VERSION ""

NS_ :

BS_:

BU_: BMS Charger DART

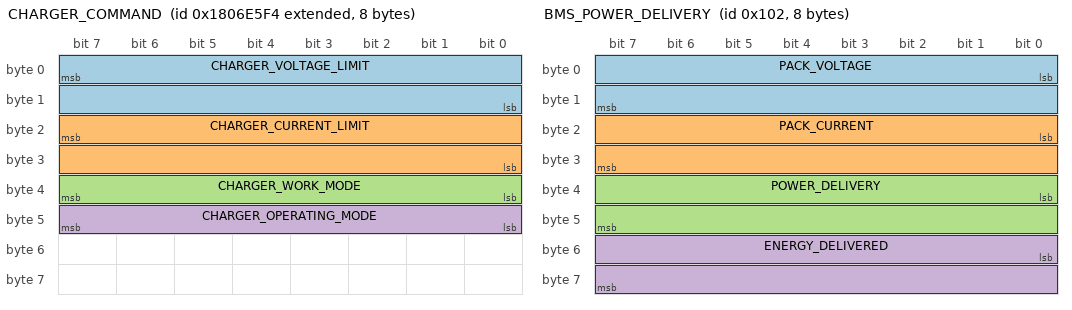
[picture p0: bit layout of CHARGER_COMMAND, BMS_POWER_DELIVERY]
BO_ 2550588916 CHARGER_COMMAND: 8 BMS
 SG_ CHARGER_VOLTAGE_LIMIT : 7|16@0+ (0.1,0) [0|680] "V" Vector__XXX
 SG_ CHARGER_CURRENT_LIMIT : 23|16@0+ (0.1,0) [0|14] "A" Vector__XXX
 SG_ CHARGER_WORK_MODE : 39|8@0+ (1,0) [0|2] "Enum" Vector__XXX
 SG_ CHARGER_OPERATING_MODE : 47|8@0+ (1,0) [0|0] "Enum" Vector__XXX

BO_ 2566869221 CHARGER_RESPONSE: 8 Charger
 SG_ CHARGER_VOLTAGE_OUTPUT : 7|16@0+ (0.1,0) [0|680] "V" Vector__XXX
 SG_ CHARGER_CURRENT_OUTPUT : 23|16@0+ (0.1,0) [0|14] "A" Vector__XXX
 SG_ CHARGER_HARDWARE_PROTECTION : 32|1@0+ (1,0) [0|1] "Bool" Vector__XXX
 SG_ CHARGER_TEMPERATURE_PROTECTION : 33|1@0+ (1,0) [0|1] "Bool" Vector__XXX
 SG_ CHARGER_INPUT_VOLTAGE_STATUS : 35|2@0+ (1,0) [0|1] "Bool" Vector__XXX
 SG_ CHARGER_OUTPUT_UNDERVOLTAGE : 36|1@0+ (1,0) [0|1] "Bool" Vector__XXX
 SG_ CHARGER_OUTPUT_OVERVOLTAGE : 37|1@0+ (1,0) [0|1] "Bool" Vector__XXX
 SG_ CHARGER_OUTPUT_OVERCURRENT : 38|1@0+ (1,0) [0|1] "Bool" Vector__XXX
 SG_ CHARGER_OUTPUT_SHORT_CIRCUIT : 39|1@0+ (1,0) [0|1] "Bool" Vector__XXX
 SG_ CHARGER_COMMAND_FAULT : 40|1@0+ (1,0) [0|1] "Bool" Vector__XXX
 SG_ CHARGER_WORK_STATUS : 42|2@0+ (1,0) [0|3] "Enum" Vector__XXX
 SG_ CHARGER_INITIALIZED : 43|1@0+ (1,0) [0|1] "Bool" Vector__XXX
 SG_ CHARGER_FAN_ENABLED : 44|1@0+ (1,0) [0|1] "Bool" Vector__XXX
 SG_ CHARGER_COOLING_PUMP_ENABLED : 45|1@0+ (1,0) [0|1] "Bool" Vector__XXX
 SG_ CHARGER_CC_STATUS : 49|2@0+ (1,0) [0|3] "Enum" Vector__XXX
 SG_ CHARGER_CP_STATUS : 50|1@0+ (1,0) [0|1] "Bool" Vector__XXX
 SG_ CHARGER_SOCKET_OVERTEMPERATURE : 51|1@0+ (1,0) [0|1] "Bool" Vector__XXX
 SG_ CHARGER_ELECTRONIC_LOCK : 54|3@0+ (1,0) [0|4] "Enum" Vector__XXX
 SG_ CHARGER_S2_SWITCH_CONTROL : 55|1@0+ (1,0) [0|1] "Bool" Vector__XXX
 SG_ CHARGER_TEMPERATURE : 63|8@0+ (1,-40) [-40|205] "C" Vector__XXX

BO_ 257 BMS_STATUS: 8 BMS
 SG_ BMS_ISOSPI_FAULT : 0|1@1+ (1,0) [0|1] "Bool" Vector__XXX
 SG_ BMS_SELF_TEST_FAULT : 1|1@1+ (1,0) [0|1] "Bool" Vector__XXX
 SG_ BMS_SENSE_LINE_FAULT : 2|1@1+ (1,0) [0|1] "Bool" Vector__XXX
 SG_ BMS_UNDERVOLTAGE_FAULT : 3|1@1+ (1,0) [0|1] "Bool" Vector__XXX
 SG_ BMS_OVERVOLTAGE_FAULT : 4|1@1+ (1,0) [0|1] "Bool" Vector__XXX
 SG_ BMS_UNDERTEMPERATURE_FAULT : 5|1@1+ (1,0) [0|1] "Bool" Vector__XXX
 SG_ BMS_OVERTEMPERATURE_FAULT : 6|1@1+ (1,0) [0|1] "Bool" Vector__XXX
 SG_ BMS_FAULT : 7|1@1+ (1,0) [0|0] "Bool" Vector__XXX
 SG_ IMD_FAULT : 8|1@1+ (1,0) [0|0] "Bool" Vector__XXX
 SG_ BMS_CHARGING : 9|1@1+ (1,0) [0|1] "Bool" Vector__XXX
 SG_ BMS_BALANCING : 10|1@1+ (1,0) [0|1] "Bool" Vector__XXX
 SG_ SHUTDOWN_VEHICLE_CLOSED : 11|1@1+ (1,0) [0|1] "Bool" Vector__XXX
 SG_ SHUTDOWN_IMD_CLOSED : 12|1@1+ (1,0) [0|1] "Bool" Vector__XXX
 SG_ SHUTDOWN_BMS_CLOSED : 13|1@1+ (1,0) [0|1] "Bool" Vector__XXX
 SG_ SHUTDOWN_MSD_TSMS_CLOSED : 14|1@1+ (1,0) [0|1] "Bool" Vector__XXX
 SG_ SHUTDOWN_LOOP_BLIP : 15|1@1+ (1,0) [0|1] "Bool" Vector__XXX
 SG_ NEGATIVE_IR_ENABLED : 16|1@1+ (1,0) [0|1] "Bool" Vector__XXX
 SG_ POSITIVE_IR_ENABLED : 17|1@1+ (1,0) [0|1] "Bool" Vector__XXX
 SG_ BMS_EEPROM_STATE : 18|2@1+ (1,0) [0|1] "Enum" Vector__XXX
 SG_ BMS_LTC_0_ISOSPI_FAULT : 32|1@1+ (1,0) [0|1] "Bool" Vector__XXX
 SG_ BMS_LTC_1_ISOSPI_FAULT : 33|1@1+ (1,0) [0|1] "Bool" Vector__XXX
 SG_ BMS_LTC_2_ISOSPI_FAULT : 34|1@1+ (1,0) [0|1] "Bool" Vector__XXX
 SG_ BMS_LTC_3_ISOSPI_FAULT : 35|1@1+ (1,0) [0|1] "Bool" Vector__XXX
 SG_ BMS_LTC_4_ISOSPI_FAULT : 36|1@1+ (1,0) [0|1] "Bool" Vector__XXX
 SG_ BMS_LTC_5_ISOSPI_FAULT : 37|1@1+ (1,0) [0|1] "Bool" Vector__XXX
 SG_ BMS_LTC_6_ISOSPI_FAULT : 38|1@1+ (1,0) [0|1] "Bool" Vector__XXX
 SG_ BMS_LTC_7_ISOSPI_FAULT : 39|1@1+ (1,0) [0|1] "Bool" Vector__XXX
 SG_ BMS_LTC_8_ISOSPI_FAULT : 40|1@1+ (1,0) [0|1] "Bool" Vector__XXX
 SG_ BMS_LTC_9_ISOSPI_FAULT : 41|1@1+ (1,0) [0|1] "Bool" Vector__XXX
 SG_ BMS_LTC_0_SELF_TEST_FAULT : 48|1@1+ (1,0) [0|1] "Bool" Vector__XXX
 SG_ BMS_LTC_1_SELF_TEST_FAULT : 49|1@1+ (1,0) [0|1] "Bool" Vector__XXX
 SG_ BMS_LTC_2_SELF_TEST_FAULT : 50|1@1+ (1,0) [0|1] "Bool" Vector__XXX
 SG_ BMS_LTC_3_SELF_TEST_FAULT : 51|1@1+ (1,0) [0|1] "Bool" Vector__XXX
 SG_ BMS_LTC_4_SELF_TEST_FAULT : 52|1@1+ (1,0) [0|1] "Bool" Vector__XXX
 SG_ BMS_LTC_5_SELF_TEST_FAULT : 53|1@1+ (1,0) [0|1] "Bool" Vector__XXX
 SG_ BMS_LTC_6_SELF_TEST_FAULT : 54|1@1+ (1,0) [0|1] "Bool" Vector__XXX
 SG_ BMS_LTC_7_SELF_TEST_FAULT : 55|1@1+ (1,0) [0|1] "Bool" Vector__XXX
 SG_ BMS_LTC_8_SELF_TEST_FAULT : 56|1@1+ (1,0) [0|1] "Bool" Vector__XXX
 SG_ BMS_LTC_9_SELF_TEST_FAULT : 57|1@1+ (1,0) [0|1] "Bool" Vector__XXX

BO_ 258 BMS_POWER_DELIVERY: 8 BMS
 SG_ PACK_VOLTAGE : 0|16@1+ (0.0125,0) [0|819.2] "V" Vector__XXX
 SG_ PACK_CURRENT : 16|16@1- (0.019073486328125,0) [-625|625] "A" Vector__XXX
 SG_ POWER_DELIVERY : 32|16@1- (0.004,0) [-131.072|131.068] "kW" Vector__XXX
 SG_ ENERGY_DELIVERED : 48|16@1- (0.5,0) [-16.384|16.3835] "Wh" Vector__XXX

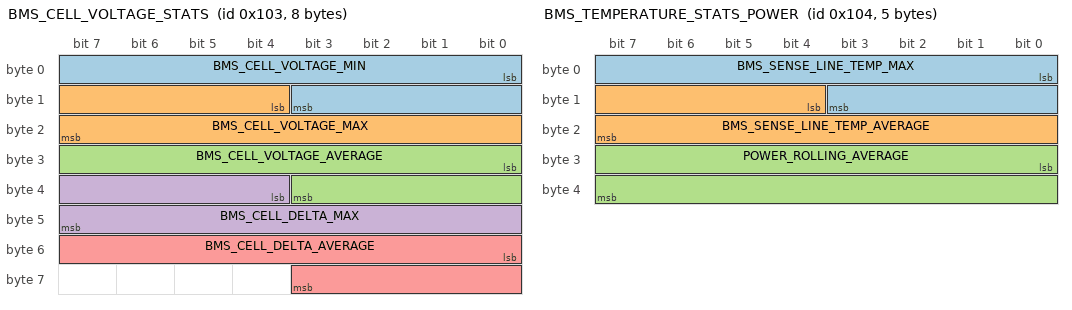
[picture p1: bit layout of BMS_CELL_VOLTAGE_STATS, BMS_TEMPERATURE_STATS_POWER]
BO_ 259 BMS_CELL_VOLTAGE_STATS: 8 Vector__XXX
 SG_ BMS_CELL_VOLTAGE_MIN : 0|12@1+ (0.0016,0) [0|6.552] "V" Vector__XXX
 SG_ BMS_CELL_VOLTAGE_MAX : 12|12@1+ (0.0016,0) [0|6.552] "V" Vector__XXX
 SG_ BMS_CELL_VOLTAGE_AVERAGE : 24|12@1+ (0.0016,0) [0|6.552] "V" Vector__XXX
 SG_ BMS_CELL_DELTA_MAX : 36|12@1+ (0.0016,0) [0|6.552] "V" Vector__XXX
 SG_ BMS_CELL_DELTA_AVERAGE : 48|12@1+ (0.0016,0) [0|6.552] "V" Vector__XXX

BO_ 260 BMS_TEMPERATURE_STATS_POWER: 5 Vector__XXX
 SG_ BMS_SENSE_LINE_TEMP_MAX : 0|12@1+ (0.0625,-106) [-106|150] "C" Vector__XXX
 SG_ BMS_SENSE_LINE_TEMP_AVERAGE : 12|12@1+ (0.0625,-106) [-106|150] "C" Vector__XXX
 SG_ POWER_ROLLING_AVERAGE : 24|16@1- (0.004,0) [-131.072|131.068] "kW" Vector__XXX

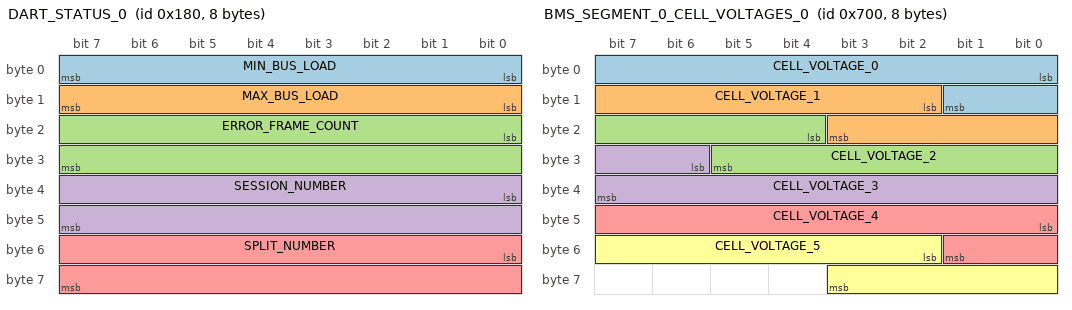
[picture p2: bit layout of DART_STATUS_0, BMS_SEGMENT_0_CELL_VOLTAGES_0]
BO_ 384 DART_STATUS_0: 8 DART
 SG_ MIN_BUS_LOAD : 0|8@1+ (0.6,0) [0|153] "%" Vector__XXX
 SG_ MAX_BUS_LOAD : 8|8@1+ (0.6,0) [0|153] "%" Vector__XXX
 SG_ ERROR_FRAME_COUNT : 16|16@1+ (1,0) [0|65535] "" Vector__XXX
 SG_ SESSION_NUMBER : 32|16@1+ (1,0) [0|65535] "" Vector__XXX
 SG_ SPLIT_NUMBER : 48|16@1+ (1,0) [0|65535] "" Vector__XXX

BO_ 1792 BMS_SEGMENT_0_CELL_VOLTAGES_0: 8 BMS
 SG_ CELL_VOLTAGE_0 : 0|10@1+ (0.0064,0) [0|6.5472] "V" Vector__XXX
 SG_ CELL_VOLTAGE_1 : 10|10@1+ (0.0064,0) [0|6.5472] "V" Vector__XXX
 SG_ CELL_VOLTAGE_2 : 20|10@1+ (0.0064,0) [0|6.5472] "V" Vector__XXX
 SG_ CELL_VOLTAGE_3 : 30|10@1+ (0.0064,0) [0|6.5472] "V" Vector__XXX
 SG_ CELL_VOLTAGE_4 : 40|10@1+ (0.0064,0) [0|6.5472] "V" Vector__XXX
 SG_ CELL_VOLTAGE_5 : 50|10@1+ (0.0064,0) [0|6.5472] "V" Vector__XXX

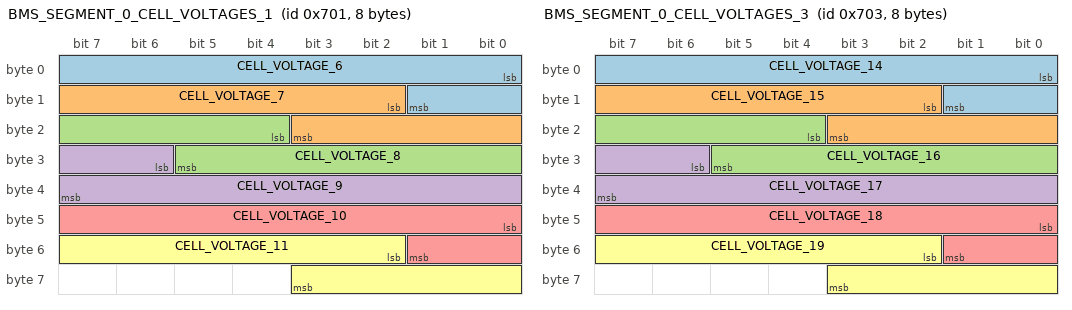
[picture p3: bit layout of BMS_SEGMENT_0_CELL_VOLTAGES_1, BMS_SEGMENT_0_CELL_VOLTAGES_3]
BO_ 1793 BMS_SEGMENT_0_CELL_VOLTAGES_1: 8 BMS
 SG_ CELL_VOLTAGE_6 : 0|10@1+ (0.0064,0) [0|6.5472] "V" Vector__XXX
 SG_ CELL_VOLTAGE_7 : 10|10@1+ (0.0064,0) [0|6.5472] "V" Vector__XXX
 SG_ CELL_VOLTAGE_8 : 20|10@1+ (0.0064,0) [0|6.5472] "V" Vector__XXX
 SG_ CELL_VOLTAGE_9 : 30|10@1+ (0.0064,0) [0|6.5472] "V" Vector__XXX
 SG_ CELL_VOLTAGE_10 : 40|10@1+ (0.0064,0) [0|6.5472] "V" Vector__XXX
 SG_ CELL_VOLTAGE_11 : 50|10@1+ (0.0064,0) [0|6.5472] "V" Vector__XXX

BO_ 1794 BMS_SEGMENT_0_CELL_VOLTAGES_2: 3 BMS
 SG_ CELL_VOLTAGE_12 : 0|10@1+ (0.0064,0) [0|6.5472] "V" Vector__XXX
 SG_ CELL_VOLTAGE_13 : 10|10@1+ (0.0064,0) [0|6.5472] "V" Vector__XXX

BO_ 1795 BMS_SEGMENT_0_CELL_VOLTAGES_3: 8 BMS
 SG_ CELL_VOLTAGE_14 : 0|10@1+ (0.0064,0) [0|6.5472] "V" Vector__XXX
 SG_ CELL_VOLTAGE_15 : 10|10@1+ (0.0064,0) [0|6.5472] "V" Vector__XXX
 SG_ CELL_VOLTAGE_16 : 20|10@1+ (0.0064,0) [0|6.5472] "V" Vector__XXX
 SG_ CELL_VOLTAGE_17 : 30|10@1+ (0.0064,0) [0|6.5472] "V" Vector__XXX
 SG_ CELL_VOLTAGE_18 : 40|10@1+ (0.0064,0) [0|6.5472] "V" Vector__XXX
 SG_ CELL_VOLTAGE_19 : 50|10@1+ (0.0064,0) [0|6.5472] "V" Vector__XXX

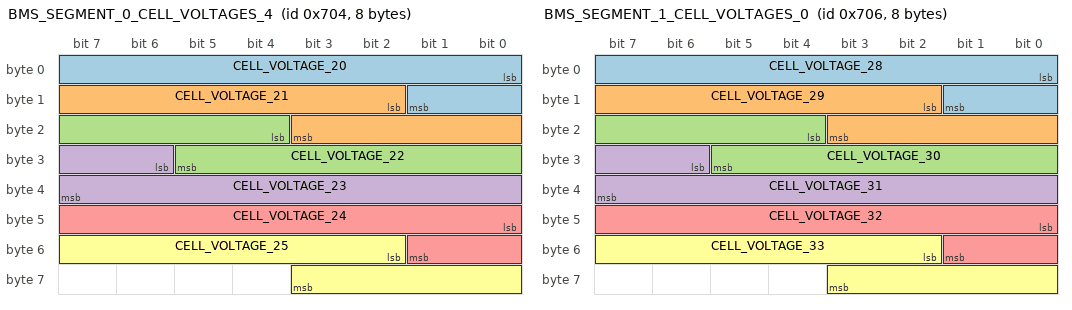
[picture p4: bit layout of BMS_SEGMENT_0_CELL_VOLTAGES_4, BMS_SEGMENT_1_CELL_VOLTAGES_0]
BO_ 1796 BMS_SEGMENT_0_CELL_VOLTAGES_4: 8 BMS
 SG_ CELL_VOLTAGE_20 : 0|10@1+ (0.0064,0) [0|6.5472] "V" Vector__XXX
 SG_ CELL_VOLTAGE_21 : 10|10@1+ (0.0064,0) [0|6.5472] "V" Vector__XXX
 SG_ CELL_VOLTAGE_22 : 20|10@1+ (0.0064,0) [0|6.5472] "V" Vector__XXX
 SG_ CELL_VOLTAGE_23 : 30|10@1+ (0.0064,0) [0|6.5472] "V" Vector__XXX
 SG_ CELL_VOLTAGE_24 : 40|10@1+ (0.0064,0) [0|6.5472] "V" Vector__XXX
 SG_ CELL_VOLTAGE_25 : 50|10@1+ (0.0064,0) [0|6.5472] "V" Vector__XXX

BO_ 1797 BMS_SEGMENT_0_CELL_VOLTAGES_5: 3 BMS
 SG_ CELL_VOLTAGE_26 : 0|10@1+ (0.0064,0) [0|6.5472] "V" Vector__XXX
 SG_ CELL_VOLTAGE_27 : 10|10@1+ (0.0064,0) [0|6.5472] "V" Vector__XXX

BO_ 1798 BMS_SEGMENT_1_CELL_VOLTAGES_0: 8 BMS
 SG_ CELL_VOLTAGE_28 : 0|10@1+ (0.0064,0) [0|6.5472] "V" Vector__XXX
 SG_ CELL_VOLTAGE_29 : 10|10@1+ (0.0064,0) [0|6.5472] "V" Vector__XXX
 SG_ CELL_VOLTAGE_30 : 20|10@1+ (0.0064,0) [0|6.5472] "V" Vector__XXX
 SG_ CELL_VOLTAGE_31 : 30|10@1+ (0.0064,0) [0|6.5472] "V" Vector__XXX
 SG_ CELL_VOLTAGE_32 : 40|10@1+ (0.0064,0) [0|6.5472] "V" Vector__XXX
 SG_ CELL_VOLTAGE_33 : 50|10@1+ (0.0064,0) [0|6.5472] "V" Vector__XXX

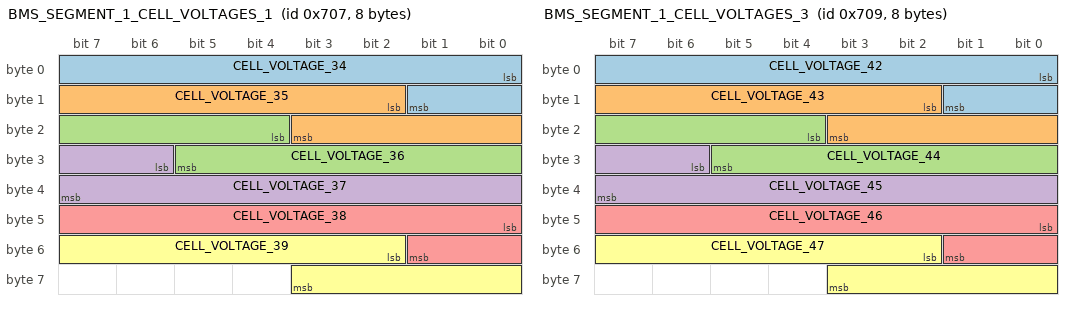
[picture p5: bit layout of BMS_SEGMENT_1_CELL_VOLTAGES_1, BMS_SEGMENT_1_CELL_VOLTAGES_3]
BO_ 1799 BMS_SEGMENT_1_CELL_VOLTAGES_1: 8 BMS
 SG_ CELL_VOLTAGE_34 : 0|10@1+ (0.0064,0) [0|6.5472] "V" Vector__XXX
 SG_ CELL_VOLTAGE_35 : 10|10@1+ (0.0064,0) [0|6.5472] "V" Vector__XXX
 SG_ CELL_VOLTAGE_36 : 20|10@1+ (0.0064,0) [0|6.5472] "V" Vector__XXX
 SG_ CELL_VOLTAGE_37 : 30|10@1+ (0.0064,0) [0|6.5472] "V" Vector__XXX
 SG_ CELL_VOLTAGE_38 : 40|10@1+ (0.0064,0) [0|6.5472] "V" Vector__XXX
 SG_ CELL_VOLTAGE_39 : 50|10@1+ (0.0064,0) [0|6.5472] "V" Vector__XXX

BO_ 1800 BMS_SEGMENT_1_CELL_VOLTAGES_2: 3 BMS
 SG_ CELL_VOLTAGE_40 : 0|10@1+ (0.0064,0) [0|6.5472] "V" Vector__XXX
 SG_ CELL_VOLTAGE_41 : 10|10@1+ (0.0064,0) [0|6.5472] "V" Vector__XXX

BO_ 1801 BMS_SEGMENT_1_CELL_VOLTAGES_3: 8 BMS
 SG_ CELL_VOLTAGE_42 : 0|10@1+ (0.0064,0) [0|6.5472] "V" Vector__XXX
 SG_ CELL_VOLTAGE_43 : 10|10@1+ (0.0064,0) [0|6.5472] "V" Vector__XXX
 SG_ CELL_VOLTAGE_44 : 20|10@1+ (0.0064,0) [0|6.5472] "V" Vector__XXX
 SG_ CELL_VOLTAGE_45 : 30|10@1+ (0.0064,0) [0|6.5472] "V" Vector__XXX
 SG_ CELL_VOLTAGE_46 : 40|10@1+ (0.0064,0) [0|6.5472] "V" Vector__XXX
 SG_ CELL_VOLTAGE_47 : 50|10@1+ (0.0064,0) [0|6.5472] "V" Vector__XXX

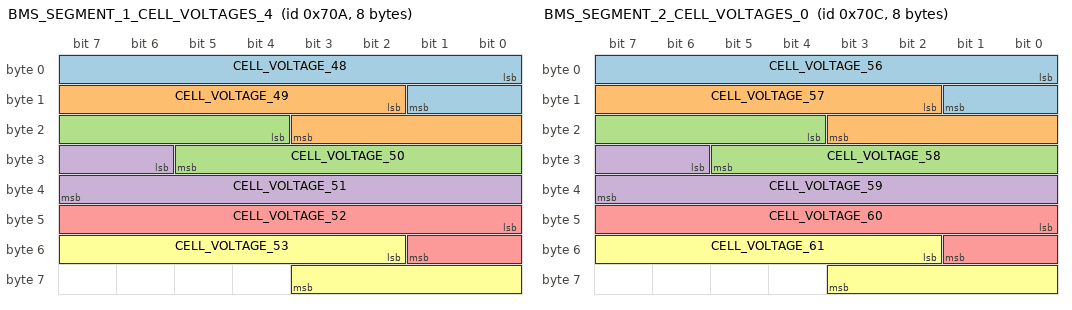
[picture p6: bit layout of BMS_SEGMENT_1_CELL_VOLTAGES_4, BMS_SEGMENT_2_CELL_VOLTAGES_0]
BO_ 1802 BMS_SEGMENT_1_CELL_VOLTAGES_4: 8 BMS
 SG_ CELL_VOLTAGE_48 : 0|10@1+ (0.0064,0) [0|6.5472] "V" Vector__XXX
 SG_ CELL_VOLTAGE_49 : 10|10@1+ (0.0064,0) [0|6.5472] "V" Vector__XXX
 SG_ CELL_VOLTAGE_50 : 20|10@1+ (0.0064,0) [0|6.5472] "V" Vector__XXX
 SG_ CELL_VOLTAGE_51 : 30|10@1+ (0.0064,0) [0|6.5472] "V" Vector__XXX
 SG_ CELL_VOLTAGE_52 : 40|10@1+ (0.0064,0) [0|6.5472] "V" Vector__XXX
 SG_ CELL_VOLTAGE_53 : 50|10@1+ (0.0064,0) [0|6.5472] "V" Vector__XXX

BO_ 1803 BMS_SEGMENT_1_CELL_VOLTAGES_5: 3 BMS
 SG_ CELL_VOLTAGE_54 : 0|10@1+ (0.0064,0) [0|6.5472] "V" Vector__XXX
 SG_ CELL_VOLTAGE_55 : 10|10@1+ (0.0064,0) [0|6.5472] "V" Vector__XXX

BO_ 1804 BMS_SEGMENT_2_CELL_VOLTAGES_0: 8 BMS
 SG_ CELL_VOLTAGE_56 : 0|10@1+ (0.0064,0) [0|6.5472] "V" Vector__XXX
 SG_ CELL_VOLTAGE_57 : 10|10@1+ (0.0064,0) [0|6.5472] "V" Vector__XXX
 SG_ CELL_VOLTAGE_58 : 20|10@1+ (0.0064,0) [0|6.5472] "V" Vector__XXX
 SG_ CELL_VOLTAGE_59 : 30|10@1+ (0.0064,0) [0|6.5472] "V" Vector__XXX
 SG_ CELL_VOLTAGE_60 : 40|10@1+ (0.0064,0) [0|6.5472] "V" Vector__XXX
 SG_ CELL_VOLTAGE_61 : 50|10@1+ (0.0064,0) [0|6.5472] "V" Vector__XXX

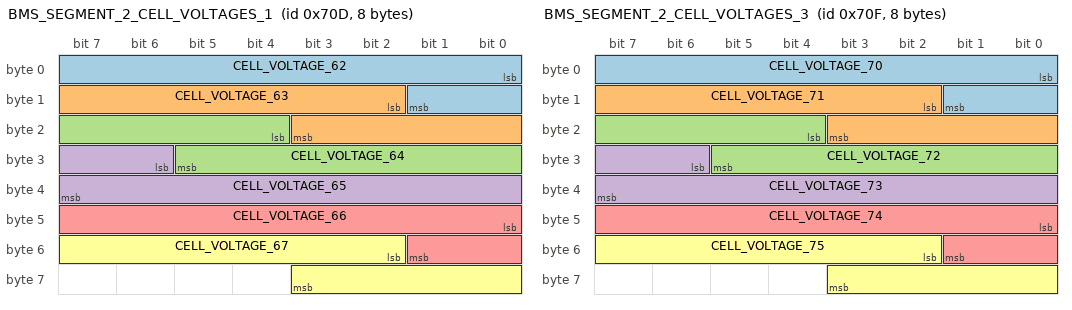
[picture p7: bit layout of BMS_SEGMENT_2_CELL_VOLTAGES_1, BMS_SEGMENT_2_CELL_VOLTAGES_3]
BO_ 1805 BMS_SEGMENT_2_CELL_VOLTAGES_1: 8 BMS
 SG_ CELL_VOLTAGE_62 : 0|10@1+ (0.0064,0) [0|6.5472] "V" Vector__XXX
 SG_ CELL_VOLTAGE_63 : 10|10@1+ (0.0064,0) [0|6.5472] "V" Vector__XXX
 SG_ CELL_VOLTAGE_64 : 20|10@1+ (0.0064,0) [0|6.5472] "V" Vector__XXX
 SG_ CELL_VOLTAGE_65 : 30|10@1+ (0.0064,0) [0|6.5472] "V" Vector__XXX
 SG_ CELL_VOLTAGE_66 : 40|10@1+ (0.0064,0) [0|6.5472] "V" Vector__XXX
 SG_ CELL_VOLTAGE_67 : 50|10@1+ (0.0064,0) [0|6.5472] "V" Vector__XXX

BO_ 1806 BMS_SEGMENT_2_CELL_VOLTAGES_2: 3 BMS
 SG_ CELL_VOLTAGE_68 : 0|10@1+ (0.0064,0) [0|6.5472] "V" Vector__XXX
 SG_ CELL_VOLTAGE_69 : 10|10@1+ (0.0064,0) [0|6.5472] "V" Vector__XXX

BO_ 1807 BMS_SEGMENT_2_CELL_VOLTAGES_3: 8 BMS
 SG_ CELL_VOLTAGE_70 : 0|10@1+ (0.0064,0) [0|6.5472] "V" Vector__XXX
 SG_ CELL_VOLTAGE_71 : 10|10@1+ (0.0064,0) [0|6.5472] "V" Vector__XXX
 SG_ CELL_VOLTAGE_72 : 20|10@1+ (0.0064,0) [0|6.5472] "V" Vector__XXX
 SG_ CELL_VOLTAGE_73 : 30|10@1+ (0.0064,0) [0|6.5472] "V" Vector__XXX
 SG_ CELL_VOLTAGE_74 : 40|10@1+ (0.0064,0) [0|6.5472] "V" Vector__XXX
 SG_ CELL_VOLTAGE_75 : 50|10@1+ (0.0064,0) [0|6.5472] "V" Vector__XXX

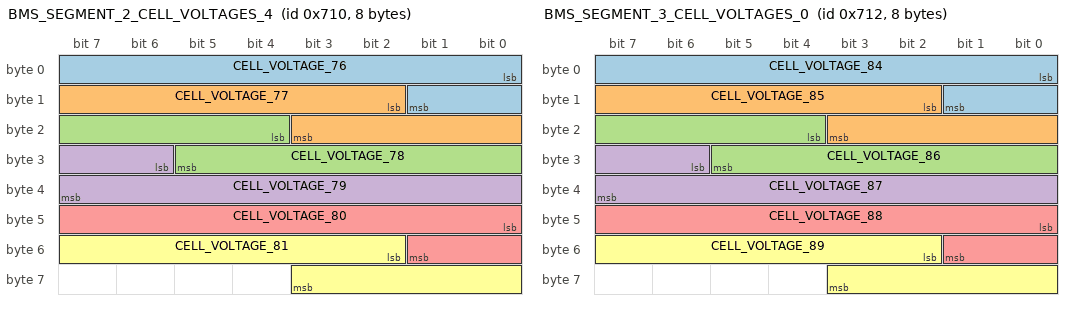
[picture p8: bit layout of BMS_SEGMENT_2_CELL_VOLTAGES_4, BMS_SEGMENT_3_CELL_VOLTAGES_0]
BO_ 1808 BMS_SEGMENT_2_CELL_VOLTAGES_4: 8 BMS
 SG_ CELL_VOLTAGE_76 : 0|10@1+ (0.0064,0) [0|6.5472] "V" Vector__XXX
 SG_ CELL_VOLTAGE_77 : 10|10@1+ (0.0064,0) [0|6.5472] "V" Vector__XXX
 SG_ CELL_VOLTAGE_78 : 20|10@1+ (0.0064,0) [0|6.5472] "V" Vector__XXX
 SG_ CELL_VOLTAGE_79 : 30|10@1+ (0.0064,0) [0|6.5472] "V" Vector__XXX
 SG_ CELL_VOLTAGE_80 : 40|10@1+ (0.0064,0) [0|6.5472] "V" Vector__XXX
 SG_ CELL_VOLTAGE_81 : 50|10@1+ (0.0064,0) [0|6.5472] "V" Vector__XXX

BO_ 1809 BMS_SEGMENT_2_CELL_VOLTAGES_5: 3 BMS
 SG_ CELL_VOLTAGE_82 : 0|10@1+ (0.0064,0) [0|6.5472] "V" Vector__XXX
 SG_ CELL_VOLTAGE_83 : 10|10@1+ (0.0064,0) [0|6.5472] "V" Vector__XXX

BO_ 1810 BMS_SEGMENT_3_CELL_VOLTAGES_0: 8 BMS
 SG_ CELL_VOLTAGE_84 : 0|10@1+ (0.0064,0) [0|6.5472] "V" Vector__XXX
 SG_ CELL_VOLTAGE_85 : 10|10@1+ (0.0064,0) [0|6.5472] "V" Vector__XXX
 SG_ CELL_VOLTAGE_86 : 20|10@1+ (0.0064,0) [0|6.5472] "V" Vector__XXX
 SG_ CELL_VOLTAGE_87 : 30|10@1+ (0.0064,0) [0|6.5472] "V" Vector__XXX
 SG_ CELL_VOLTAGE_88 : 40|10@1+ (0.0064,0) [0|6.5472] "V" Vector__XXX
 SG_ CELL_VOLTAGE_89 : 50|10@1+ (0.0064,0) [0|6.5472] "V" Vector__XXX

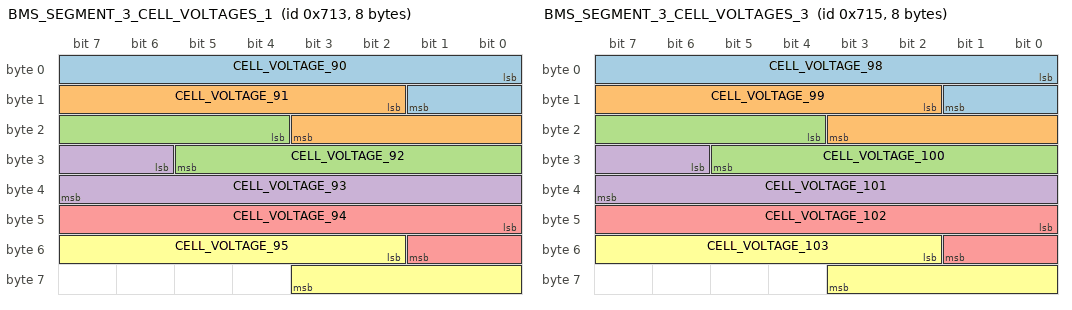
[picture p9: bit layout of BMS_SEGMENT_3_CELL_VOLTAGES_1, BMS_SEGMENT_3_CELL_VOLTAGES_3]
BO_ 1811 BMS_SEGMENT_3_CELL_VOLTAGES_1: 8 BMS
 SG_ CELL_VOLTAGE_90 : 0|10@1+ (0.0064,0) [0|6.5472] "V" Vector__XXX
 SG_ CELL_VOLTAGE_91 : 10|10@1+ (0.0064,0) [0|6.5472] "V" Vector__XXX
 SG_ CELL_VOLTAGE_92 : 20|10@1+ (0.0064,0) [0|6.5472] "V" Vector__XXX
 SG_ CELL_VOLTAGE_93 : 30|10@1+ (0.0064,0) [0|6.5472] "V" Vector__XXX
 SG_ CELL_VOLTAGE_94 : 40|10@1+ (0.0064,0) [0|6.5472] "V" Vector__XXX
 SG_ CELL_VOLTAGE_95 : 50|10@1+ (0.0064,0) [0|6.5472] "V" Vector__XXX

BO_ 1812 BMS_SEGMENT_3_CELL_VOLTAGES_2: 3 BMS
 SG_ CELL_VOLTAGE_96 : 0|10@1+ (0.0064,0) [0|6.5472] "V" Vector__XXX
 SG_ CELL_VOLTAGE_97 : 10|10@1+ (0.0064,0) [0|6.5472] "V" Vector__XXX

BO_ 1813 BMS_SEGMENT_3_CELL_VOLTAGES_3: 8 BMS
 SG_ CELL_VOLTAGE_98 : 0|10@1+ (0.0064,0) [0|6.5472] "V" Vector__XXX
 SG_ CELL_VOLTAGE_99 : 10|10@1+ (0.0064,0) [0|6.5472] "V" Vector__XXX
 SG_ CELL_VOLTAGE_100 : 20|10@1+ (0.0064,0) [0|6.5472] "V" Vector__XXX
 SG_ CELL_VOLTAGE_101 : 30|10@1+ (0.0064,0) [0|6.5472] "V" Vector__XXX
 SG_ CELL_VOLTAGE_102 : 40|10@1+ (0.0064,0) [0|6.5472] "V" Vector__XXX
 SG_ CELL_VOLTAGE_103 : 50|10@1+ (0.0064,0) [0|6.5472] "V" Vector__XXX

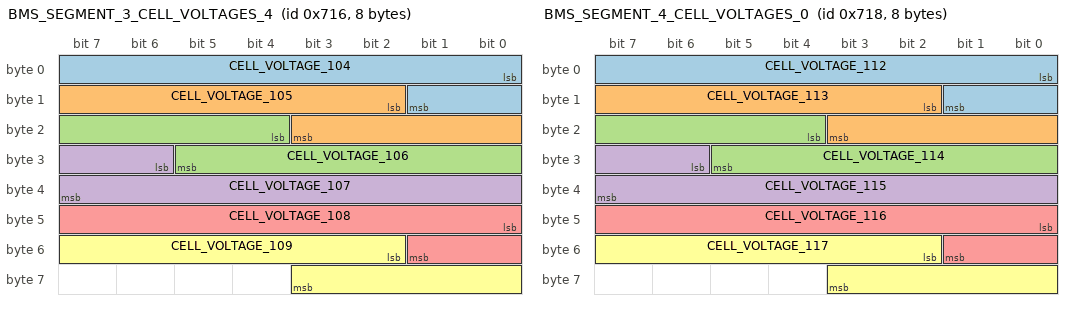
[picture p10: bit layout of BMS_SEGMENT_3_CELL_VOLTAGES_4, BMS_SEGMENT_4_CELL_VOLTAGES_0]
BO_ 1814 BMS_SEGMENT_3_CELL_VOLTAGES_4: 8 BMS
 SG_ CELL_VOLTAGE_104 : 0|10@1+ (0.0064,0) [0|6.5472] "V" Vector__XXX
 SG_ CELL_VOLTAGE_105 : 10|10@1+ (0.0064,0) [0|6.5472] "V" Vector__XXX
 SG_ CELL_VOLTAGE_106 : 20|10@1+ (0.0064,0) [0|6.5472] "V" Vector__XXX
 SG_ CELL_VOLTAGE_107 : 30|10@1+ (0.0064,0) [0|6.5472] "V" Vector__XXX
 SG_ CELL_VOLTAGE_108 : 40|10@1+ (0.0064,0) [0|6.5472] "V" Vector__XXX
 SG_ CELL_VOLTAGE_109 : 50|10@1+ (0.0064,0) [0|6.5472] "V" Vector__XXX

BO_ 1815 BMS_SEGMENT_3_CELL_VOLTAGES_5: 3 BMS
 SG_ CELL_VOLTAGE_110 : 0|10@1+ (0.0064,0) [0|6.5472] "V" Vector__XXX
 SG_ CELL_VOLTAGE_111 : 10|10@1+ (0.0064,0) [0|6.5472] "V" Vector__XXX

BO_ 1816 BMS_SEGMENT_4_CELL_VOLTAGES_0: 8 BMS
 SG_ CELL_VOLTAGE_112 : 0|10@1+ (0.0064,0) [0|6.5472] "V" Vector__XXX
 SG_ CELL_VOLTAGE_113 : 10|10@1+ (0.0064,0) [0|6.5472] "V" Vector__XXX
 SG_ CELL_VOLTAGE_114 : 20|10@1+ (0.0064,0) [0|6.5472] "V" Vector__XXX
 SG_ CELL_VOLTAGE_115 : 30|10@1+ (0.0064,0) [0|6.5472] "V" Vector__XXX
 SG_ CELL_VOLTAGE_116 : 40|10@1+ (0.0064,0) [0|6.5472] "V" Vector__XXX
 SG_ CELL_VOLTAGE_117 : 50|10@1+ (0.0064,0) [0|6.5472] "V" Vector__XXX

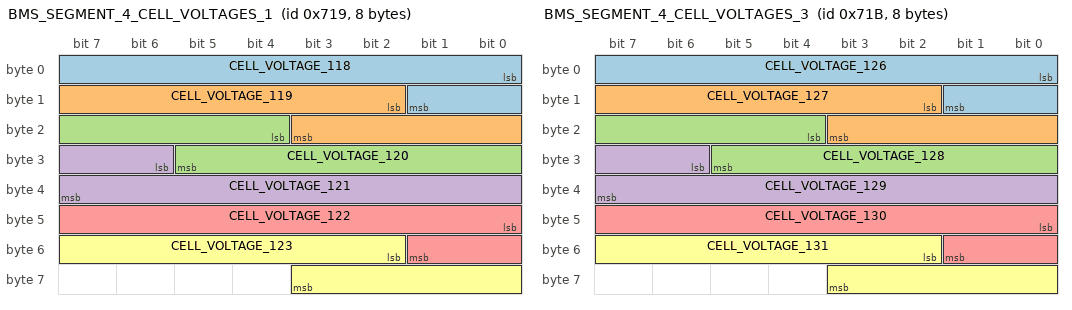
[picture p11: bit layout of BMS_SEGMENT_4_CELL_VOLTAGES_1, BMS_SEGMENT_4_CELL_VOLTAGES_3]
BO_ 1817 BMS_SEGMENT_4_CELL_VOLTAGES_1: 8 BMS
 SG_ CELL_VOLTAGE_118 : 0|10@1+ (0.0064,0) [0|6.5472] "V" Vector__XXX
 SG_ CELL_VOLTAGE_119 : 10|10@1+ (0.0064,0) [0|6.5472] "V" Vector__XXX
 SG_ CELL_VOLTAGE_120 : 20|10@1+ (0.0064,0) [0|6.5472] "V" Vector__XXX
 SG_ CELL_VOLTAGE_121 : 30|10@1+ (0.0064,0) [0|6.5472] "V" Vector__XXX
 SG_ CELL_VOLTAGE_122 : 40|10@1+ (0.0064,0) [0|6.5472] "V" Vector__XXX
 SG_ CELL_VOLTAGE_123 : 50|10@1+ (0.0064,0) [0|6.5472] "V" Vector__XXX

BO_ 1818 BMS_SEGMENT_4_CELL_VOLTAGES_2: 3 BMS
 SG_ CELL_VOLTAGE_124 : 0|10@1+ (0.0064,0) [0|6.5472] "V" Vector__XXX
 SG_ CELL_VOLTAGE_125 : 10|10@1+ (0.0064,0) [0|6.5472] "V" Vector__XXX

BO_ 1819 BMS_SEGMENT_4_CELL_VOLTAGES_3: 8 BMS
 SG_ CELL_VOLTAGE_126 : 0|10@1+ (0.0064,0) [0|6.5472] "V" Vector__XXX
 SG_ CELL_VOLTAGE_127 : 10|10@1+ (0.0064,0) [0|6.5472] "V" Vector__XXX
 SG_ CELL_VOLTAGE_128 : 20|10@1+ (0.0064,0) [0|6.5472] "V" Vector__XXX
 SG_ CELL_VOLTAGE_129 : 30|10@1+ (0.0064,0) [0|6.5472] "V" Vector__XXX
 SG_ CELL_VOLTAGE_130 : 40|10@1+ (0.0064,0) [0|6.5472] "V" Vector__XXX
 SG_ CELL_VOLTAGE_131 : 50|10@1+ (0.0064,0) [0|6.5472] "V" Vector__XXX

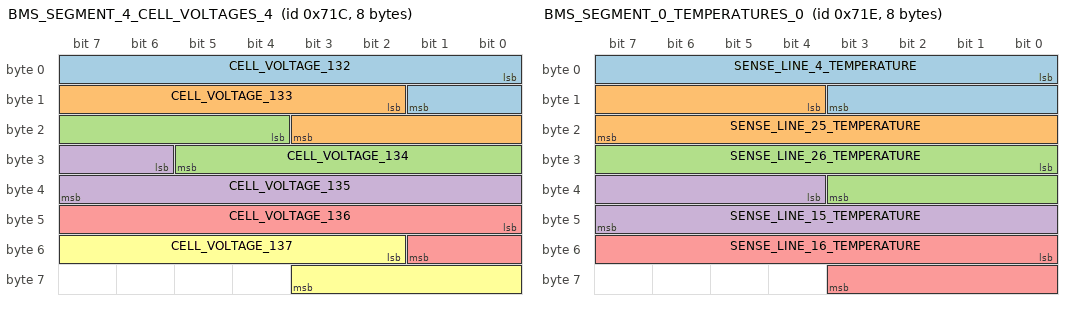
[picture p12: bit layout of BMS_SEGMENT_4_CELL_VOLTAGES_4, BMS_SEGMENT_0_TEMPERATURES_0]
BO_ 1820 BMS_SEGMENT_4_CELL_VOLTAGES_4: 8 BMS
 SG_ CELL_VOLTAGE_132 : 0|10@1+ (0.0064,0) [0|6.5472] "V" Vector__XXX
 SG_ CELL_VOLTAGE_133 : 10|10@1+ (0.0064,0) [0|6.5472] "V" Vector__XXX
 SG_ CELL_VOLTAGE_134 : 20|10@1+ (0.0064,0) [0|6.5472] "V" Vector__XXX
 SG_ CELL_VOLTAGE_135 : 30|10@1+ (0.0064,0) [0|6.5472] "V" Vector__XXX
 SG_ CELL_VOLTAGE_136 : 40|10@1+ (0.0064,0) [0|6.5472] "V" Vector__XXX
 SG_ CELL_VOLTAGE_137 : 50|10@1+ (0.0064,0) [0|6.5472] "V" Vector__XXX

BO_ 1821 BMS_SEGMENT_4_CELL_VOLTAGES_5: 3 BMS
 SG_ CELL_VOLTAGE_138 : 0|10@1+ (0.0064,0) [0|6.5472] "V" Vector__XXX
 SG_ CELL_VOLTAGE_139 : 10|10@1+ (0.0064,0) [0|6.5472] "V" Vector__XXX

BO_ 1822 BMS_SEGMENT_0_TEMPERATURES_0: 8 BMS
 SG_ SENSE_LINE_4_TEMPERATURE : 0|12@1+ (0.0625,-106) [-106|150] "C" Vector__XXX
 SG_ SENSE_LINE_25_TEMPERATURE : 12|12@1+ (0.0625,-106) [-106|150] "C" Vector__XXX
 SG_ SENSE_LINE_26_TEMPERATURE : 24|12@1+ (0.0625,-106) [-106|150] "C" Vector__XXX
 SG_ SENSE_LINE_15_TEMPERATURE : 36|12@1+ (0.0625,-106) [-106|150] "C" Vector__XXX
 SG_ SENSE_LINE_16_TEMPERATURE : 48|12@1+ (0.0625,-106) [-106|150] "C" Vector__XXX

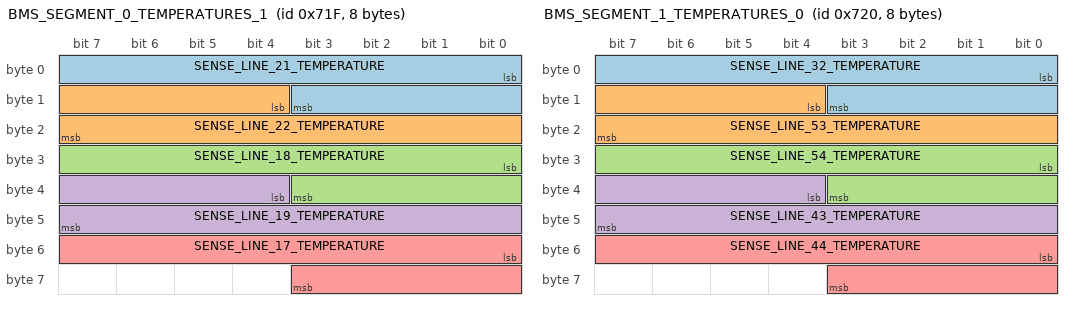
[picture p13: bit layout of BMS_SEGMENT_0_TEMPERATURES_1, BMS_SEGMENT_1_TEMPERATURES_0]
BO_ 1823 BMS_SEGMENT_0_TEMPERATURES_1: 8 BMS
 SG_ SENSE_LINE_21_TEMPERATURE : 0|12@1+ (0.0625,-106) [-106|150] "C" Vector__XXX
 SG_ SENSE_LINE_22_TEMPERATURE : 12|12@1+ (0.0625,-106) [-106|150] "C" Vector__XXX
 SG_ SENSE_LINE_18_TEMPERATURE : 24|12@1+ (0.0625,-106) [-106|150] "C" Vector__XXX
 SG_ SENSE_LINE_19_TEMPERATURE : 36|12@1+ (0.0625,-106) [-106|150] "C" Vector__XXX
 SG_ SENSE_LINE_17_TEMPERATURE : 48|12@1+ (0.0625,-106) [-106|150] "C" Vector__XXX

BO_ 1824 BMS_SEGMENT_1_TEMPERATURES_0: 8 BMS
 SG_ SENSE_LINE_32_TEMPERATURE : 0|12@1+ (0.0625,-106) [-106|150] "C" Vector__XXX
 SG_ SENSE_LINE_53_TEMPERATURE : 12|12@1+ (0.0625,-106) [-106|150] "C" Vector__XXX
 SG_ SENSE_LINE_54_TEMPERATURE : 24|12@1+ (0.0625,-106) [-106|150] "C" Vector__XXX
 SG_ SENSE_LINE_43_TEMPERATURE : 36|12@1+ (0.0625,-106) [-106|150] "C" Vector__XXX
 SG_ SENSE_LINE_44_TEMPERATURE : 48|12@1+ (0.0625,-106) [-106|150] "C" Vector__XXX

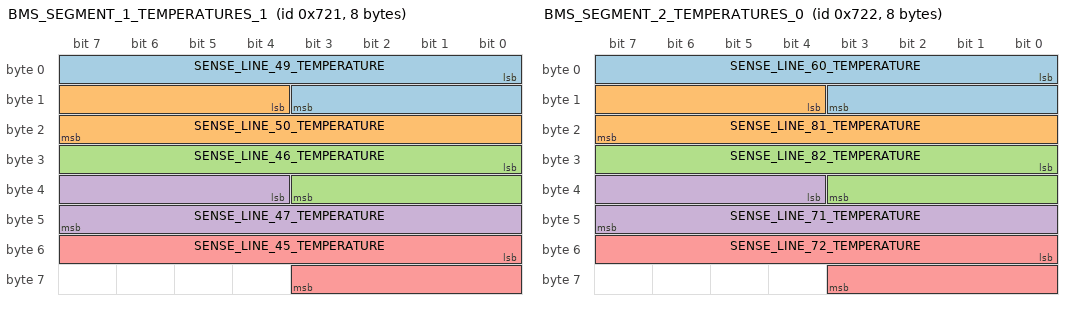
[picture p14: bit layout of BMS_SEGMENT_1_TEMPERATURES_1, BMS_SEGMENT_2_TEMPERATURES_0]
BO_ 1825 BMS_SEGMENT_1_TEMPERATURES_1: 8 BMS
 SG_ SENSE_LINE_49_TEMPERATURE : 0|12@1+ (0.0625,-106) [-106|150] "C" Vector__XXX
 SG_ SENSE_LINE_50_TEMPERATURE : 12|12@1+ (0.0625,-106) [-106|150] "C" Vector__XXX
 SG_ SENSE_LINE_46_TEMPERATURE : 24|12@1+ (0.0625,-106) [-106|150] "C" Vector__XXX
 SG_ SENSE_LINE_47_TEMPERATURE : 36|12@1+ (0.0625,-106) [-106|150] "C" Vector__XXX
 SG_ SENSE_LINE_45_TEMPERATURE : 48|12@1+ (0.0625,-106) [-106|150] "C" Vector__XXX

BO_ 1826 BMS_SEGMENT_2_TEMPERATURES_0: 8 BMS
 SG_ SENSE_LINE_60_TEMPERATURE : 0|12@1+ (0.0625,-106) [-106|150] "C" Vector__XXX
 SG_ SENSE_LINE_81_TEMPERATURE : 12|12@1+ (0.0625,-106) [-106|150] "C" Vector__XXX
 SG_ SENSE_LINE_82_TEMPERATURE : 24|12@1+ (0.0625,-106) [-106|150] "C" Vector__XXX
 SG_ SENSE_LINE_71_TEMPERATURE : 36|12@1+ (0.0625,-106) [-106|150] "C" Vector__XXX
 SG_ SENSE_LINE_72_TEMPERATURE : 48|12@1+ (0.0625,-106) [-106|150] "C" Vector__XXX

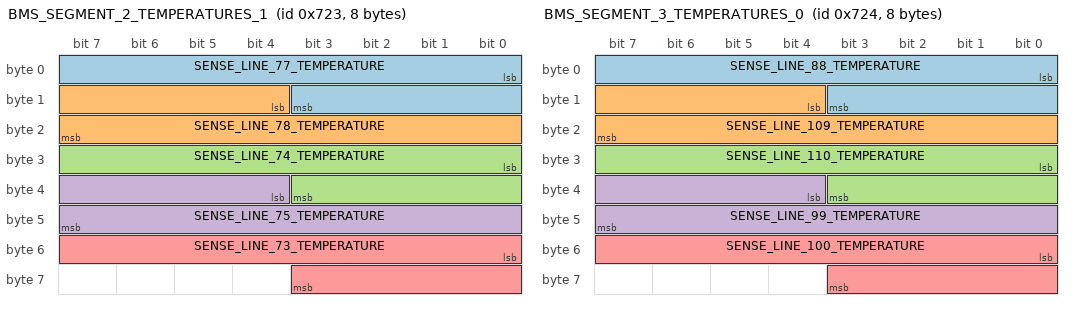
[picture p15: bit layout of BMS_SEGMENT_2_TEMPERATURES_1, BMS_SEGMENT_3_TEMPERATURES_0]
BO_ 1827 BMS_SEGMENT_2_TEMPERATURES_1: 8 BMS
 SG_ SENSE_LINE_77_TEMPERATURE : 0|12@1+ (0.0625,-106) [-106|150] "C" Vector__XXX
 SG_ SENSE_LINE_78_TEMPERATURE : 12|12@1+ (0.0625,-106) [-106|150] "C" Vector__XXX
 SG_ SENSE_LINE_74_TEMPERATURE : 24|12@1+ (0.0625,-106) [-106|150] "C" Vector__XXX
 SG_ SENSE_LINE_75_TEMPERATURE : 36|12@1+ (0.0625,-106) [-106|150] "C" Vector__XXX
 SG_ SENSE_LINE_73_TEMPERATURE : 48|12@1+ (0.0625,-106) [-106|150] "C" Vector__XXX

BO_ 1828 BMS_SEGMENT_3_TEMPERATURES_0: 8 BMS
 SG_ SENSE_LINE_88_TEMPERATURE : 0|12@1+ (0.0625,-106) [-106|150] "C" Vector__XXX
 SG_ SENSE_LINE_109_TEMPERATURE : 12|12@1+ (0.0625,-106) [-106|150] "C" Vector__XXX
 SG_ SENSE_LINE_110_TEMPERATURE : 24|12@1+ (0.0625,-106) [-106|150] "C" Vector__XXX
 SG_ SENSE_LINE_99_TEMPERATURE : 36|12@1+ (0.0625,-106) [-106|150] "C" Vector__XXX
 SG_ SENSE_LINE_100_TEMPERATURE : 48|12@1+ (0.0625,-106) [-106|150] "C" Vector__XXX

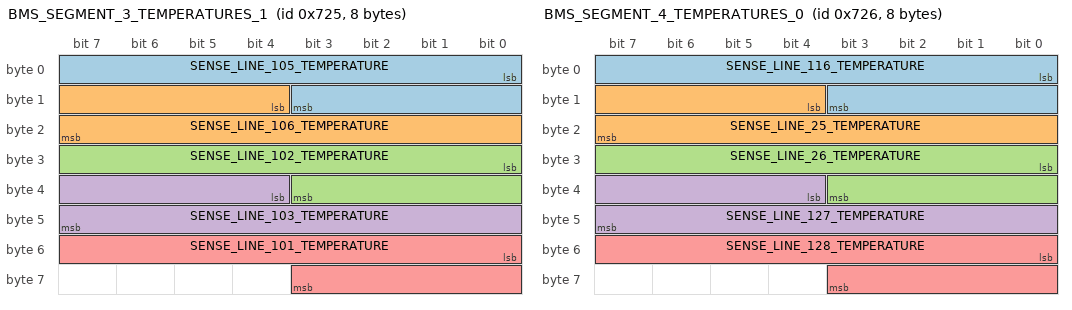
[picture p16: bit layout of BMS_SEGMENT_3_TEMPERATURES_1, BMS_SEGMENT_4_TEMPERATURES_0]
BO_ 1829 BMS_SEGMENT_3_TEMPERATURES_1: 8 BMS
 SG_ SENSE_LINE_105_TEMPERATURE : 0|12@1+ (0.0625,-106) [-106|150] "C" Vector__XXX
 SG_ SENSE_LINE_106_TEMPERATURE : 12|12@1+ (0.0625,-106) [-106|150] "C" Vector__XXX
 SG_ SENSE_LINE_102_TEMPERATURE : 24|12@1+ (0.0625,-106) [-106|150] "C" Vector__XXX
 SG_ SENSE_LINE_103_TEMPERATURE : 36|12@1+ (0.0625,-106) [-106|150] "C" Vector__XXX
 SG_ SENSE_LINE_101_TEMPERATURE : 48|12@1+ (0.0625,-106) [-106|150] "C" Vector__XXX

BO_ 1830 BMS_SEGMENT_4_TEMPERATURES_0: 8 BMS
 SG_ SENSE_LINE_116_TEMPERATURE : 0|12@1+ (0.0625,-106) [-106|150] "C" Vector__XXX
 SG_ SENSE_LINE_25_TEMPERATURE : 12|12@1+ (0.0625,-106) [-106|150] "C" Vector__XXX
 SG_ SENSE_LINE_26_TEMPERATURE : 24|12@1+ (0.0625,-106) [-106|150] "C" Vector__XXX
 SG_ SENSE_LINE_127_TEMPERATURE : 36|12@1+ (0.0625,-106) [-106|150] "C" Vector__XXX
 SG_ SENSE_LINE_128_TEMPERATURE : 48|12@1+ (0.0625,-106) [-106|150] "C" Vector__XXX

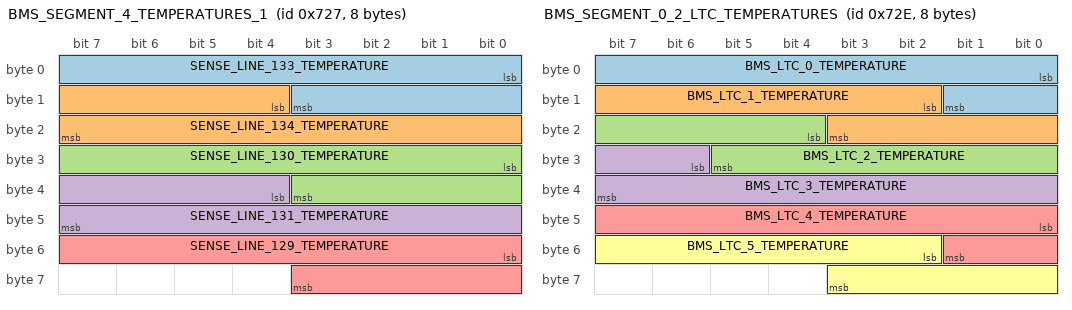
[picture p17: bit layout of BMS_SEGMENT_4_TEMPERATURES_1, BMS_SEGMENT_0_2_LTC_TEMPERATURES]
BO_ 1831 BMS_SEGMENT_4_TEMPERATURES_1: 8 BMS
 SG_ SENSE_LINE_133_TEMPERATURE : 0|12@1+ (0.0625,-106) [-106|150] "C" Vector__XXX
 SG_ SENSE_LINE_134_TEMPERATURE : 12|12@1+ (0.0625,-106) [-106|150] "C" Vector__XXX
 SG_ SENSE_LINE_130_TEMPERATURE : 24|12@1+ (0.0625,-106) [-106|150] "C" Vector__XXX
 SG_ SENSE_LINE_131_TEMPERATURE : 36|12@1+ (0.0625,-106) [-106|150] "C" Vector__XXX
 SG_ SENSE_LINE_129_TEMPERATURE : 48|12@1+ (0.0625,-106) [-106|150] "C" Vector__XXX

BO_ 1832 BMS_SEGMENT_0_1_SENSE_LINE_STATUSES: 8 BMS
 SG_ SENSE_LINE_0_HI_OPEN : 0|1@1+ (1,0) [0|1] "Bool" Vector__XXX
 SG_ SENSE_LINE_1_OPEN : 1|1@1+ (1,0) [0|1] "Bool" Vector__XXX
 SG_ SENSE_LINE_2_OPEN : 2|1@1+ (1,0) [0|1] "Bool" Vector__XXX
 SG_ SENSE_LINE_3_OPEN : 3|1@1+ (1,0) [0|1] "Bool" Vector__XXX
 SG_ SENSE_LINE_4_OPEN : 4|1@1+ (1,0) [0|1] "Bool" Vector__XXX
 SG_ SENSE_LINE_5_OPEN : 5|1@1+ (1,0) [0|1] "Bool" Vector__XXX
 SG_ SENSE_LINE_6_OPEN : 6|1@1+ (1,0) [0|1] "Bool" Vector__XXX
 SG_ SENSE_LINE_7_OPEN : 7|1@1+ (1,0) [0|1] "Bool" Vector__XXX
 SG_ SENSE_LINE_8_OPEN : 8|1@1+ (1,0) [0|1] "Bool" Vector__XXX
 SG_ SENSE_LINE_9_OPEN : 9|1@1+ (1,0) [0|1] "Bool" Vector__XXX
 SG_ SENSE_LINE_10_OPEN : 10|1@1+ (1,0) [0|1] "Bool" Vector__XXX
 SG_ SENSE_LINE_11_OPEN : 11|1@1+ (1,0) [0|1] "Bool" Vector__XXX
 SG_ SENSE_LINE_12_OPEN : 12|1@1+ (1,0) [0|1] "Bool" Vector__XXX
 SG_ SENSE_LINE_13_OPEN : 13|1@1+ (1,0) [0|1] "Bool" Vector__XXX
 SG_ SENSE_LINE_14_LO_OPEN : 14|1@1+ (1,0) [0|1] "Bool" Vector__XXX
 SG_ SENSE_LINE_14_HI_OPEN : 16|1@1+ (1,0) [0|1] "Bool" Vector__XXX
 SG_ SENSE_LINE_15_OPEN : 17|1@1+ (1,0) [0|1] "Bool" Vector__XXX
 SG_ SENSE_LINE_16_OPEN : 18|1@1+ (1,0) [0|1] "Bool" Vector__XXX
 SG_ SENSE_LINE_17_OPEN : 19|1@1+ (1,0) [0|1] "Bool" Vector__XXX
 SG_ SENSE_LINE_18_OPEN : 20|1@1+ (1,0) [0|1] "Bool" Vector__XXX
 SG_ SENSE_LINE_19_OPEN : 21|1@1+ (1,0) [0|1] "Bool" Vector__XXX
 SG_ SENSE_LINE_20_OPEN : 22|1@1+ (1,0) [0|1] "Bool" Vector__XXX
 SG_ SENSE_LINE_21_OPEN : 23|1@1+ (1,0) [0|1] "Bool" Vector__XXX
 SG_ SENSE_LINE_22_OPEN : 24|1@1+ (1,0) [0|1] "Bool" Vector__XXX
 SG_ SENSE_LINE_23_OPEN : 25|1@1+ (1,0) [0|1] "Bool" Vector__XXX
 SG_ SENSE_LINE_24_OPEN : 26|1@1+ (1,0) [0|1] "Bool" Vector__XXX
 SG_ SENSE_LINE_25_OPEN : 27|1@1+ (1,0) [0|1] "Bool" Vector__XXX
 SG_ SENSE_LINE_26_OPEN : 28|1@1+ (1,0) [0|1] "Bool" Vector__XXX
 SG_ SENSE_LINE_27_OPEN : 29|1@1+ (1,0) [0|1] "Bool" Vector__XXX
 SG_ SENSE_LINE_28_LO_OPEN : 30|1@1+ (1,0) [0|1] "Bool" Vector__XXX
 SG_ SENSE_LINE_28_HI_OPEN : 32|1@1+ (1,0) [0|1] "Bool" Vector__XXX
 SG_ SENSE_LINE_29_OPEN : 33|1@1+ (1,0) [0|1] "Bool" Vector__XXX
 SG_ SENSE_LINE_30_OPEN : 34|1@1+ (1,0) [0|1] "Bool" Vector__XXX
 SG_ SENSE_LINE_31_OPEN : 35|1@1+ (1,0) [0|1] "Bool" Vector__XXX
 SG_ SENSE_LINE_32_OPEN : 36|1@1+ (1,0) [0|1] "Bool" Vector__XXX
 SG_ SENSE_LINE_33_OPEN : 37|1@1+ (1,0) [0|1] "Bool" Vector__XXX
 SG_ SENSE_LINE_34_OPEN : 38|1@1+ (1,0) [0|1] "Bool" Vector__XXX
 SG_ SENSE_LINE_35_OPEN : 39|1@1+ (1,0) [0|1] "Bool" Vector__XXX
 SG_ SENSE_LINE_36_OPEN : 40|1@1+ (1,0) [0|1] "Bool" Vector__XXX
 SG_ SENSE_LINE_37_OPEN : 41|1@1+ (1,0) [0|1] "Bool" Vector__XXX
 SG_ SENSE_LINE_38_OPEN : 42|1@1+ (1,0) [0|1] "Bool" Vector__XXX
 SG_ SENSE_LINE_39_OPEN : 43|1@1+ (1,0) [0|1] "Bool" Vector__XXX
 SG_ SENSE_LINE_40_OPEN : 44|1@1+ (1,0) [0|1] "Bool" Vector__XXX
 SG_ SENSE_LINE_41_OPEN : 45|1@1+ (1,0) [0|1] "Bool" Vector__XXX
 SG_ SENSE_LINE_42_LO_OPEN : 46|1@1+ (1,0) [0|1] "Bool" Vector__XXX
 SG_ SENSE_LINE_42_HI_OPEN : 48|1@1+ (1,0) [0|1] "Bool" Vector__XXX
 SG_ SENSE_LINE_43_OPEN : 49|1@1+ (1,0) [0|1] "Bool" Vector__XXX
 SG_ SENSE_LINE_44_OPEN : 50|1@1+ (1,0) [0|1] "Bool" Vector__XXX
 SG_ SENSE_LINE_45_OPEN : 51|1@1+ (1,0) [0|1] "Bool" Vector__XXX
 SG_ SENSE_LINE_46_OPEN : 52|1@1+ (1,0) [0|1] "Bool" Vector__XXX
 SG_ SENSE_LINE_47_OPEN : 53|1@1+ (1,0) [0|1] "Bool" Vector__XXX
 SG_ SENSE_LINE_48_OPEN : 54|1@1+ (1,0) [0|1] "Bool" Vector__XXX
 SG_ SENSE_LINE_49_OPEN : 55|1@1+ (1,0) [0|1] "Bool" Vector__XXX
 SG_ SENSE_LINE_50_OPEN : 56|1@1+ (1,0) [0|1] "Bool" Vector__XXX
 SG_ SENSE_LINE_51_OPEN : 57|1@1+ (1,0) [0|1] "Bool" Vector__XXX
 SG_ SENSE_LINE_52_OPEN : 58|1@1+ (1,0) [0|1] "Bool" Vector__XXX
 SG_ SENSE_LINE_53_OPEN : 59|1@1+ (1,0) [0|1] "Bool" Vector__XXX
 SG_ SENSE_LINE_54_OPEN : 60|1@1+ (1,0) [0|1] "Bool" Vector__XXX
 SG_ SENSE_LINE_55_OPEN : 61|1@1+ (1,0) [0|1] "Bool" Vector__XXX
 SG_ SENSE_LINE_56_LO_OPEN : 62|1@1+ (1,0) [0|1] "Bool" Vector__XXX

BO_ 1833 BMS_SEGMENT_2_3_SENSE_LINE_STATUSES: 8 BMS
 SG_ SENSE_LINE_56_HI_OPEN : 0|1@1+ (1,0) [0|1] "Bool" Vector__XXX
 SG_ SENSE_LINE_57_OPEN : 1|1@1+ (1,0) [0|1] "Bool" Vector__XXX
 SG_ SENSE_LINE_58_OPEN : 2|1@1+ (1,0) [0|1] "Bool" Vector__XXX
 SG_ SENSE_LINE_59_OPEN : 3|1@1+ (1,0) [0|1] "Bool" Vector__XXX
 SG_ SENSE_LINE_60_OPEN : 4|1@1+ (1,0) [0|1] "Bool" Vector__XXX
 SG_ SENSE_LINE_61_OPEN : 5|1@1+ (1,0) [0|1] "Bool" Vector__XXX
 SG_ SENSE_LINE_62_OPEN : 6|1@1+ (1,0) [0|1] "Bool" Vector__XXX
 SG_ SENSE_LINE_63_OPEN : 7|1@1+ (1,0) [0|1] "Bool" Vector__XXX
 SG_ SENSE_LINE_64_OPEN : 8|1@1+ (1,0) [0|1] "Bool" Vector__XXX
 SG_ SENSE_LINE_65_OPEN : 9|1@1+ (1,0) [0|1] "Bool" Vector__XXX
 SG_ SENSE_LINE_66_OPEN : 10|1@1+ (1,0) [0|1] "Bool" Vector__XXX
 SG_ SENSE_LINE_67_OPEN : 11|1@1+ (1,0) [0|1] "Bool" Vector__XXX
 SG_ SENSE_LINE_68_OPEN : 12|1@1+ (1,0) [0|1] "Bool" Vector__XXX
 SG_ SENSE_LINE_69_OPEN : 13|1@1+ (1,0) [0|1] "Bool" Vector__XXX
 SG_ SENSE_LINE_70_LO_OPEN : 14|1@1+ (1,0) [0|1] "Bool" Vector__XXX
 SG_ SENSE_LINE_70_HI_OPEN : 16|1@1+ (1,0) [0|1] "Bool" Vector__XXX
 SG_ SENSE_LINE_71_OPEN : 17|1@1+ (1,0) [0|1] "Bool" Vector__XXX
 SG_ SENSE_LINE_72_OPEN : 18|1@1+ (1,0) [0|1] "Bool" Vector__XXX
 SG_ SENSE_LINE_73_OPEN : 19|1@1+ (1,0) [0|1] "Bool" Vector__XXX
 SG_ SENSE_LINE_74_OPEN : 20|1@1+ (1,0) [0|1] "Bool" Vector__XXX
 SG_ SENSE_LINE_75_OPEN : 21|1@1+ (1,0) [0|1] "Bool" Vector__XXX
 SG_ SENSE_LINE_76_OPEN : 22|1@1+ (1,0) [0|1] "Bool" Vector__XXX
 SG_ SENSE_LINE_77_OPEN : 23|1@1+ (1,0) [0|1] "Bool" Vector__XXX
 SG_ SENSE_LINE_78_OPEN : 24|1@1+ (1,0) [0|1] "Bool" Vector__XXX
 SG_ SENSE_LINE_79_OPEN : 25|1@1+ (1,0) [0|1] "Bool" Vector__XXX
 SG_ SENSE_LINE_80_OPEN : 26|1@1+ (1,0) [0|1] "Bool" Vector__XXX
 SG_ SENSE_LINE_81_OPEN : 27|1@1+ (1,0) [0|1] "Bool" Vector__XXX
 SG_ SENSE_LINE_82_OPEN : 28|1@1+ (1,0) [0|1] "Bool" Vector__XXX
 SG_ SENSE_LINE_83_OPEN : 29|1@1+ (1,0) [0|1] "Bool" Vector__XXX
 SG_ SENSE_LINE_84_LO_OPEN : 30|1@1+ (1,0) [0|1] "Bool" Vector__XXX
 SG_ SENSE_LINE_84_HI_OPEN : 32|1@1+ (1,0) [0|1] "Bool" Vector__XXX
 SG_ SENSE_LINE_85_OPEN : 33|1@1+ (1,0) [0|1] "Bool" Vector__XXX
 SG_ SENSE_LINE_86_OPEN : 34|1@1+ (1,0) [0|1] "Bool" Vector__XXX
 SG_ SENSE_LINE_87_OPEN : 35|1@1+ (1,0) [0|1] "Bool" Vector__XXX
 SG_ SENSE_LINE_88_OPEN : 36|1@1+ (1,0) [0|1] "Bool" Vector__XXX
 SG_ SENSE_LINE_89_OPEN : 37|1@1+ (1,0) [0|1] "Bool" Vector__XXX
 SG_ SENSE_LINE_90_OPEN : 38|1@1+ (1,0) [0|1] "Bool" Vector__XXX
 SG_ SENSE_LINE_91_OPEN : 39|1@1+ (1,0) [0|1] "Bool" Vector__XXX
 SG_ SENSE_LINE_92_OPEN : 40|1@1+ (1,0) [0|1] "Bool" Vector__XXX
 SG_ SENSE_LINE_93_OPEN : 41|1@1+ (1,0) [0|1] "Bool" Vector__XXX
 SG_ SENSE_LINE_94_OPEN : 42|1@1+ (1,0) [0|1] "Bool" Vector__XXX
 SG_ SENSE_LINE_95_OPEN : 43|1@1+ (1,0) [0|1] "Bool" Vector__XXX
 SG_ SENSE_LINE_96_OPEN : 44|1@1+ (1,0) [0|1] "Bool" Vector__XXX
 SG_ SENSE_LINE_97_OPEN : 45|1@1+ (1,0) [0|1] "Bool" Vector__XXX
 SG_ SENSE_LINE_98_LO_OPEN : 46|1@1+ (1,0) [0|1] "Bool" Vector__XXX
 SG_ SENSE_LINE_98_HI_OPEN : 48|1@1+ (1,0) [0|1] "Bool" Vector__XXX
 SG_ SENSE_LINE_99_OPEN : 49|1@1+ (1,0) [0|1] "Bool" Vector__XXX
 SG_ SENSE_LINE_100_OPEN : 50|1@1+ (1,0) [0|1] "Bool" Vector__XXX
 SG_ SENSE_LINE_101_OPEN : 51|1@1+ (1,0) [0|1] "Bool" Vector__XXX
 SG_ SENSE_LINE_102_OPEN : 52|1@1+ (1,0) [0|1] "Bool" Vector__XXX
 SG_ SENSE_LINE_103_OPEN : 53|1@1+ (1,0) [0|1] "Bool" Vector__XXX
 SG_ SENSE_LINE_104_OPEN : 54|1@1+ (1,0) [0|1] "Bool" Vector__XXX
 SG_ SENSE_LINE_105_OPEN : 55|1@1+ (1,0) [0|1] "Bool" Vector__XXX
 SG_ SENSE_LINE_106_OPEN : 56|1@1+ (1,0) [0|1] "Bool" Vector__XXX
 SG_ SENSE_LINE_107_OPEN : 57|1@1+ (1,0) [0|1] "Bool" Vector__XXX
 SG_ SENSE_LINE_108_OPEN : 58|1@1+ (1,0) [0|1] "Bool" Vector__XXX
 SG_ SENSE_LINE_109_OPEN : 59|1@1+ (1,0) [0|1] "Bool" Vector__XXX
 SG_ SENSE_LINE_110_OPEN : 60|1@1+ (1,0) [0|1] "Bool" Vector__XXX
 SG_ SENSE_LINE_111_OPEN : 61|1@1+ (1,0) [0|1] "Bool" Vector__XXX
 SG_ SENSE_LINE_112_LO_OPEN : 62|1@1+ (1,0) [0|1] "Bool" Vector__XXX

BO_ 1834 BMS_SEGMENT_4_SENSE_LINE_STATUSES: 4 BMS
 SG_ SENSE_LINE_112_HI_OPEN : 0|1@1+ (1,0) [0|1] "Bool" Vector__XXX
 SG_ SENSE_LINE_113_OPEN : 1|1@1+ (1,0) [0|1] "Bool" Vector__XXX
 SG_ SENSE_LINE_114_OPEN : 2|1@1+ (1,0) [0|1] "Bool" Vector__XXX
 SG_ SENSE_LINE_115_OPEN : 3|1@1+ (1,0) [0|1] "Bool" Vector__XXX
 SG_ SENSE_LINE_116_OPEN : 4|1@1+ (1,0) [0|1] "Bool" Vector__XXX
 SG_ SENSE_LINE_117_OPEN : 5|1@1+ (1,0) [0|1] "Bool" Vector__XXX
 SG_ SENSE_LINE_118_OPEN : 6|1@1+ (1,0) [0|1] "Bool" Vector__XXX
 SG_ SENSE_LINE_119_OPEN : 7|1@1+ (1,0) [0|1] "Bool" Vector__XXX
 SG_ SENSE_LINE_120_OPEN : 8|1@1+ (1,0) [0|1] "Bool" Vector__XXX
 SG_ SENSE_LINE_121_OPEN : 9|1@1+ (1,0) [0|1] "Bool" Vector__XXX
 SG_ SENSE_LINE_122_OPEN : 10|1@1+ (1,0) [0|1] "Bool" Vector__XXX
 SG_ SENSE_LINE_123_OPEN : 11|1@1+ (1,0) [0|1] "Bool" Vector__XXX
 SG_ SENSE_LINE_124_OPEN : 12|1@1+ (1,0) [0|1] "Bool" Vector__XXX
 SG_ SENSE_LINE_125_OPEN : 13|1@1+ (1,0) [0|1] "Bool" Vector__XXX
 SG_ SENSE_LINE_126_LO_OPEN : 14|1@1+ (1,0) [0|1] "Bool" Vector__XXX
 SG_ SENSE_LINE_126_HI_OPEN : 16|1@1+ (1,0) [0|1] "Bool" Vector__XXX
 SG_ SENSE_LINE_127_OPEN : 17|1@1+ (1,0) [0|1] "Bool" Vector__XXX
 SG_ SENSE_LINE_128_OPEN : 18|1@1+ (1,0) [0|1] "Bool" Vector__XXX
 SG_ SENSE_LINE_129_OPEN : 19|1@1+ (1,0) [0|1] "Bool" Vector__XXX
 SG_ SENSE_LINE_130_OPEN : 20|1@1+ (1,0) [0|1] "Bool" Vector__XXX
 SG_ SENSE_LINE_131_OPEN : 21|1@1+ (1,0) [0|1] "Bool" Vector__XXX
 SG_ SENSE_LINE_132_OPEN : 22|1@1+ (1,0) [0|1] "Bool" Vector__XXX
 SG_ SENSE_LINE_133_OPEN : 23|1@1+ (1,0) [0|1] "Bool" Vector__XXX
 SG_ SENSE_LINE_134_OPEN : 24|1@1+ (1,0) [0|1] "Bool" Vector__XXX
 SG_ SENSE_LINE_135_OPEN : 25|1@1+ (1,0) [0|1] "Bool" Vector__XXX
 SG_ SENSE_LINE_136_OPEN : 26|1@1+ (1,0) [0|1] "Bool" Vector__XXX
 SG_ SENSE_LINE_137_OPEN : 27|1@1+ (1,0) [0|1] "Bool" Vector__XXX
 SG_ SENSE_LINE_138_OPEN : 28|1@1+ (1,0) [0|1] "Bool" Vector__XXX
 SG_ SENSE_LINE_139_OPEN : 29|1@1+ (1,0) [0|1] "Bool" Vector__XXX
 SG_ SENSE_LINE_140_LO_OPEN : 30|1@1+ (1,0) [0|1] "Bool" Vector__XXX

BO_ 1835 BMS_SEGMENT_0_1_BALANCING: 8 BMS
 SG_ CELL_BALANCING_0 : 0|1@1+ (1,0) [0|1] "Bool" Vector__XXX
 SG_ CELL_BALANCING_1 : 1|1@1+ (1,0) [0|1] "Bool" Vector__XXX
 SG_ CELL_BALANCING_2 : 2|1@1+ (1,0) [0|1] "Bool" Vector__XXX
 SG_ CELL_BALANCING_3 : 3|1@1+ (1,0) [0|1] "Bool" Vector__XXX
 SG_ CELL_BALANCING_4 : 4|1@1+ (1,0) [0|1] "Bool" Vector__XXX
 SG_ CELL_BALANCING_5 : 5|1@1+ (1,0) [0|1] "Bool" Vector__XXX
 SG_ CELL_BALANCING_6 : 6|1@1+ (1,0) [0|1] "Bool" Vector__XXX
 SG_ CELL_BALANCING_7 : 7|1@1+ (1,0) [0|1] "Bool" Vector__XXX
 SG_ CELL_BALANCING_8 : 8|1@1+ (1,0) [0|1] "Bool" Vector__XXX
 SG_ CELL_BALANCING_9 : 9|1@1+ (1,0) [0|1] "Bool" Vector__XXX
 SG_ CELL_BALANCING_10 : 10|1@1+ (1,0) [0|1] "Bool" Vector__XXX
 SG_ CELL_BALANCING_11 : 11|1@1+ (1,0) [0|1] "Bool" Vector__XXX
 SG_ CELL_BALANCING_12 : 12|1@1+ (1,0) [0|1] "Bool" Vector__XXX
 SG_ CELL_BALANCING_13 : 13|1@1+ (1,0) [0|1] "Bool" Vector__XXX
 SG_ CELL_BALANCING_14 : 16|1@1+ (1,0) [0|1] "Bool" Vector__XXX
 SG_ CELL_BALANCING_15 : 17|1@1+ (1,0) [0|1] "Bool" Vector__XXX
 SG_ CELL_BALANCING_16 : 18|1@1+ (1,0) [0|1] "Bool" Vector__XXX
 SG_ CELL_BALANCING_17 : 19|1@1+ (1,0) [0|1] "Bool" Vector__XXX
 SG_ CELL_BALANCING_18 : 20|1@1+ (1,0) [0|1] "Bool" Vector__XXX
 SG_ CELL_BALANCING_19 : 21|1@1+ (1,0) [0|1] "Bool" Vector__XXX
 SG_ CELL_BALANCING_20 : 22|1@1+ (1,0) [0|1] "Bool" Vector__XXX
 SG_ CELL_BALANCING_21 : 23|1@1+ (1,0) [0|1] "Bool" Vector__XXX
 SG_ CELL_BALANCING_22 : 24|1@1+ (1,0) [0|1] "Bool" Vector__XXX
 SG_ CELL_BALANCING_23 : 25|1@1+ (1,0) [0|1] "Bool" Vector__XXX
 SG_ CELL_BALANCING_24 : 26|1@1+ (1,0) [0|1] "Bool" Vector__XXX
 SG_ CELL_BALANCING_25 : 27|1@1+ (1,0) [0|1] "Bool" Vector__XXX
 SG_ CELL_BALANCING_26 : 28|1@1+ (1,0) [0|1] "Bool" Vector__XXX
 SG_ CELL_BALANCING_27 : 29|1@1+ (1,0) [0|1] "Bool" Vector__XXX
 SG_ CELL_BALANCING_28 : 32|1@1+ (1,0) [0|1] "Bool" Vector__XXX
 SG_ CELL_BALANCING_29 : 33|1@1+ (1,0) [0|1] "Bool" Vector__XXX
 SG_ CELL_BALANCING_39 : 34|1@1+ (1,0) [0|1] "Bool" Vector__XXX
 SG_ CELL_BALANCING_31 : 35|1@1+ (1,0) [0|1] "Bool" Vector__XXX
 SG_ CELL_BALANCING_32 : 36|1@1+ (1,0) [0|1] "Bool" Vector__XXX
 SG_ CELL_BALANCING_33 : 37|1@1+ (1,0) [0|1] "Bool" Vector__XXX
 SG_ CELL_BALANCING_34 : 38|1@1+ (1,0) [0|1] "Bool" Vector__XXX
 SG_ CELL_BALANCING_35 : 39|1@1+ (1,0) [0|1] "Bool" Vector__XXX
 SG_ CELL_BALANCING_36 : 40|1@1+ (1,0) [0|1] "Bool" Vector__XXX
 SG_ CELL_BALANCING_37 : 41|1@1+ (1,0) [0|1] "Bool" Vector__XXX
 SG_ CELL_BALANCING_38 : 42|1@1+ (1,0) [0|1] "Bool" Vector__XXX
 SG_ CELL_BALANCING_30 : 43|1@1+ (1,0) [0|1] "Bool" Vector__XXX
 SG_ CELL_BALANCING_40 : 44|1@1+ (1,0) [0|1] "Bool" Vector__XXX
 SG_ CELL_BALANCING_41 : 45|1@1+ (1,0) [0|1] "Bool" Vector__XXX
 SG_ CELL_BALANCING_42 : 48|1@1+ (1,0) [0|1] "Bool" Vector__XXX
 SG_ CELL_BALANCING_43 : 49|1@1+ (1,0) [0|1] "Bool" Vector__XXX
 SG_ CELL_BALANCING_44 : 50|1@1+ (1,0) [0|1] "Bool" Vector__XXX
 SG_ CELL_BALANCING_45 : 51|1@1+ (1,0) [0|1] "Bool" Vector__XXX
 SG_ CELL_BALANCING_46 : 52|1@1+ (1,0) [0|1] "Bool" Vector__XXX
 SG_ CELL_BALANCING_47 : 53|1@1+ (1,0) [0|1] "Bool" Vector__XXX
 SG_ CELL_BALANCING_48 : 54|1@1+ (1,0) [0|1] "Bool" Vector__XXX
 SG_ CELL_BALANCING_49 : 55|1@1+ (1,0) [0|1] "Bool" Vector__XXX
 SG_ CELL_BALANCING_50 : 56|1@1+ (1,0) [0|1] "Bool" Vector__XXX
 SG_ CELL_BALANCING_51 : 57|1@1+ (1,0) [0|1] "Bool" Vector__XXX
 SG_ CELL_BALANCING_52 : 58|1@1+ (1,0) [0|1] "Bool" Vector__XXX
 SG_ CELL_BALANCING_53 : 59|1@1+ (1,0) [0|1] "Bool" Vector__XXX
 SG_ CELL_BALANCING_54 : 60|1@1+ (1,0) [0|1] "Bool" Vector__XXX
 SG_ CELL_BALANCING_55 : 61|1@1+ (1,0) [0|1] "Bool" Vector__XXX

BO_ 1836 BMS_SEGMENT_2_3_BALANCING: 8 BMS
 SG_ CELL_BALANCING_56 : 0|1@1+ (1,0) [0|1] "Bool" Vector__XXX
 SG_ CELL_BALANCING_57 : 1|1@1+ (1,0) [0|1] "Bool" Vector__XXX
 SG_ CELL_BALANCING_58 : 2|1@1+ (1,0) [0|1] "Bool" Vector__XXX
 SG_ CELL_BALANCING_59 : 3|1@1+ (1,0) [0|1] "Bool" Vector__XXX
 SG_ CELL_BALANCING_60 : 4|1@1+ (1,0) [0|1] "Bool" Vector__XXX
 SG_ CELL_BALANCING_61 : 5|1@1+ (1,0) [0|1] "Bool" Vector__XXX
 SG_ CELL_BALANCING_62 : 6|1@1+ (1,0) [0|1] "Bool" Vector__XXX
 SG_ CELL_BALANCING_63 : 7|1@1+ (1,0) [0|1] "Bool" Vector__XXX
 SG_ CELL_BALANCING_64 : 8|1@1+ (1,0) [0|1] "Bool" Vector__XXX
 SG_ CELL_BALANCING_65 : 9|1@1+ (1,0) [0|1] "Bool" Vector__XXX
 SG_ CELL_BALANCING_66 : 10|1@1+ (1,0) [0|1] "Bool" Vector__XXX
 SG_ CELL_BALANCING_67 : 11|1@1+ (1,0) [0|1] "Bool" Vector__XXX
 SG_ CELL_BALANCING_68 : 12|1@1+ (1,0) [0|1] "Bool" Vector__XXX
 SG_ CELL_BALANCING_69 : 13|1@1+ (1,0) [0|1] "Bool" Vector__XXX
 SG_ CELL_BALANCING_70 : 16|1@1+ (1,0) [0|1] "Bool" Vector__XXX
 SG_ CELL_BALANCING_71 : 17|1@1+ (1,0) [0|1] "Bool" Vector__XXX
 SG_ CELL_BALANCING_72 : 18|1@1+ (1,0) [0|1] "Bool" Vector__XXX
 SG_ CELL_BALANCING_73 : 19|1@1+ (1,0) [0|1] "Bool" Vector__XXX
 SG_ CELL_BALANCING_74 : 20|1@1+ (1,0) [0|1] "Bool" Vector__XXX
 SG_ CELL_BALANCING_75 : 21|1@1+ (1,0) [0|1] "Bool" Vector__XXX
 SG_ CELL_BALANCING_76 : 22|1@1+ (1,0) [0|1] "Bool" Vector__XXX
 SG_ CELL_BALANCING_77 : 23|1@1+ (1,0) [0|1] "Bool" Vector__XXX
 SG_ CELL_BALANCING_78 : 24|1@1+ (1,0) [0|1] "Bool" Vector__XXX
 SG_ CELL_BALANCING_79 : 25|1@1+ (1,0) [0|1] "Bool" Vector__XXX
 SG_ CELL_BALANCING_80 : 26|1@1+ (1,0) [0|1] "Bool" Vector__XXX
 SG_ CELL_BALANCING_81 : 27|1@1+ (1,0) [0|1] "Bool" Vector__XXX
 SG_ CELL_BALANCING_82 : 28|1@1+ (1,0) [0|1] "Bool" Vector__XXX
 SG_ CELL_BALANCING_83 : 29|1@1+ (1,0) [0|1] "Bool" Vector__XXX
 SG_ CELL_BALANCING_84 : 32|1@1+ (1,0) [0|1] "Bool" Vector__XXX
 SG_ CELL_BALANCING_85 : 33|1@1+ (1,0) [0|1] "Bool" Vector__XXX
 SG_ CELL_BALANCING_86 : 34|1@1+ (1,0) [0|1] "Bool" Vector__XXX
 SG_ CELL_BALANCING_87 : 35|1@1+ (1,0) [0|1] "Bool" Vector__XXX
 SG_ CELL_BALANCING_88 : 36|1@1+ (1,0) [0|1] "Bool" Vector__XXX
 SG_ CELL_BALANCING_89 : 37|1@1+ (1,0) [0|1] "Bool" Vector__XXX
 SG_ CELL_BALANCING_90 : 38|1@1+ (1,0) [0|1] "Bool" Vector__XXX
 SG_ CELL_BALANCING_91 : 39|1@1+ (1,0) [0|1] "Bool" Vector__XXX
 SG_ CELL_BALANCING_92 : 40|1@1+ (1,0) [0|1] "Bool" Vector__XXX
 SG_ CELL_BALANCING_93 : 41|1@1+ (1,0) [0|1] "Bool" Vector__XXX
 SG_ CELL_BALANCING_94 : 42|1@1+ (1,0) [0|1] "Bool" Vector__XXX
 SG_ CELL_BALANCING_95 : 43|1@1+ (1,0) [0|1] "Bool" Vector__XXX
 SG_ CELL_BALANCING_96 : 44|1@1+ (1,0) [0|1] "Bool" Vector__XXX
 SG_ CELL_BALANCING_97 : 45|1@1+ (1,0) [0|1] "Bool" Vector__XXX
 SG_ CELL_BALANCING_98 : 48|1@1+ (1,0) [0|1] "Bool" Vector__XXX
 SG_ CELL_BALANCING_99 : 49|1@1+ (1,0) [0|1] "Bool" Vector__XXX
 SG_ CELL_BALANCING_100 : 50|1@1+ (1,0) [0|1] "Bool" Vector__XXX
 SG_ CELL_BALANCING_101 : 51|1@1+ (1,0) [0|1] "Bool" Vector__XXX
 SG_ CELL_BALANCING_102 : 52|1@1+ (1,0) [0|1] "Bool" Vector__XXX
 SG_ CELL_BALANCING_103 : 53|1@1+ (1,0) [0|1] "Bool" Vector__XXX
 SG_ CELL_BALANCING_104 : 54|1@1+ (1,0) [0|1] "Bool" Vector__XXX
 SG_ CELL_BALANCING_105 : 55|1@1+ (1,0) [0|1] "Bool" Vector__XXX
 SG_ CELL_BALANCING_106 : 56|1@1+ (1,0) [0|1] "Bool" Vector__XXX
 SG_ CELL_BALANCING_107 : 57|1@1+ (1,0) [0|1] "Bool" Vector__XXX
 SG_ CELL_BALANCING_108 : 58|1@1+ (1,0) [0|1] "Bool" Vector__XXX
 SG_ CELL_BALANCING_109 : 59|1@1+ (1,0) [0|1] "Bool" Vector__XXX
 SG_ CELL_BALANCING_110 : 60|1@1+ (1,0) [0|1] "Bool" Vector__XXX
 SG_ CELL_BALANCING_111 : 61|1@1+ (1,0) [0|1] "Bool" Vector__XXX

BO_ 1837 BMS_SEGMENT_4_BALANCING: 4 BMS
 SG_ CELL_BALANCING_112 : 0|1@1+ (1,0) [0|1] "Bool" Vector__XXX
 SG_ CELL_BALANCING_113 : 1|1@1+ (1,0) [0|1] "Bool" Vector__XXX
 SG_ CELL_BALANCING_114 : 2|1@1+ (1,0) [0|1] "Bool" Vector__XXX
 SG_ CELL_BALANCING_115 : 3|1@1+ (1,0) [0|1] "Bool" Vector__XXX
 SG_ CELL_BALANCING_116 : 4|1@1+ (1,0) [0|1] "Bool" Vector__XXX
 SG_ CELL_BALANCING_117 : 5|1@1+ (1,0) [0|1] "Bool" Vector__XXX
 SG_ CELL_BALANCING_118 : 6|1@1+ (1,0) [0|1] "Bool" Vector__XXX
 SG_ CELL_BALANCING_119 : 7|1@1+ (1,0) [0|1] "Bool" Vector__XXX
 SG_ CELL_BALANCING_120 : 8|1@1+ (1,0) [0|1] "Bool" Vector__XXX
 SG_ CELL_BALANCING_121 : 9|1@1+ (1,0) [0|1] "Bool" Vector__XXX
 SG_ CELL_BALANCING_122 : 10|1@1+ (1,0) [0|1] "Bool" Vector__XXX
 SG_ CELL_BALANCING_123 : 11|1@1+ (1,0) [0|1] "Bool" Vector__XXX
 SG_ CELL_BALANCING_124 : 12|1@1+ (1,0) [0|1] "Bool" Vector__XXX
 SG_ CELL_BALANCING_125 : 13|1@1+ (1,0) [0|1] "Bool" Vector__XXX
 SG_ CELL_BALANCING_126 : 16|1@1+ (1,0) [0|1] "Bool" Vector__XXX
 SG_ CELL_BALANCING_127 : 17|1@1+ (1,0) [0|1] "Bool" Vector__XXX
 SG_ CELL_BALANCING_128 : 18|1@1+ (1,0) [0|1] "Bool" Vector__XXX
 SG_ CELL_BALANCING_129 : 19|1@1+ (1,0) [0|1] "Bool" Vector__XXX
 SG_ CELL_BALANCING_130 : 20|1@1+ (1,0) [0|1] "Bool" Vector__XXX
 SG_ CELL_BALANCING_131 : 21|1@1+ (1,0) [0|1] "Bool" Vector__XXX
 SG_ CELL_BALANCING_132 : 22|1@1+ (1,0) [0|1] "Bool" Vector__XXX
 SG_ CELL_BALANCING_133 : 23|1@1+ (1,0) [0|1] "Bool" Vector__XXX
 SG_ CELL_BALANCING_134 : 24|1@1+ (1,0) [0|1] "Bool" Vector__XXX
 SG_ CELL_BALANCING_135 : 25|1@1+ (1,0) [0|1] "Bool" Vector__XXX
 SG_ CELL_BALANCING_136 : 26|1@1+ (1,0) [0|1] "Bool" Vector__XXX
 SG_ CELL_BALANCING_137 : 27|1@1+ (1,0) [0|1] "Bool" Vector__XXX
 SG_ CELL_BALANCING_138 : 28|1@1+ (1,0) [0|1] "Bool" Vector__XXX
 SG_ CELL_BALANCING_139 : 29|1@1+ (1,0) [0|1] "Bool" Vector__XXX

BO_ 1838 BMS_SEGMENT_0_2_LTC_TEMPERATURES: 8 BMS
 SG_ BMS_LTC_0_TEMPERATURE : 0|10@1+ (0.125,-28) [-28|100] "C" Vector__XXX
 SG_ BMS_LTC_1_TEMPERATURE : 10|10@1+ (0.125,-28) [-28|100] "C" Vector__XXX
 SG_ BMS_LTC_2_TEMPERATURE : 20|10@1+ (0.125,-28) [-28|100] "C" Vector__XXX
 SG_ BMS_LTC_3_TEMPERATURE : 30|10@1+ (0.125,-28) [-28|100] "C" Vector__XXX
 SG_ BMS_LTC_4_TEMPERATURE : 40|10@1+ (0.125,-28) [-28|100] "C" Vector__XXX
 SG_ BMS_LTC_5_TEMPERATURE : 50|10@1+ (0.125,-28) [-28|100] "C" Vector__XXX

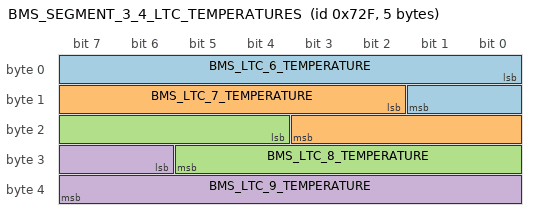
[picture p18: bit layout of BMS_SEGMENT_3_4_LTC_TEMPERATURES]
BO_ 1839 BMS_SEGMENT_3_4_LTC_TEMPERATURES: 5 BMS
 SG_ BMS_LTC_6_TEMPERATURE : 0|10@1+ (0.125,-28) [-28|100] "C" Vector__XXX
 SG_ BMS_LTC_7_TEMPERATURE : 10|10@1+ (0.125,-28) [-28|100] "C" Vector__XXX
 SG_ BMS_LTC_8_TEMPERATURE : 20|10@1+ (0.125,-28) [-28|100] "C" Vector__XXX
 SG_ BMS_LTC_9_TEMPERATURE : 30|10@1+ (0.125,-28) [-28|100] "C" Vector__XXX

BA_DEF_  "BusType" STRING ;
BA_DEF_DEF_  "BusType" "CAN";

CM_ SG_ 1012 CHARGER_OPERATING_MODE "Must be 0.";
